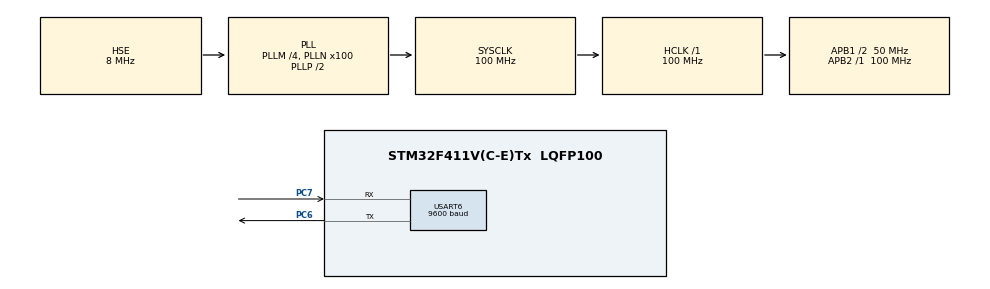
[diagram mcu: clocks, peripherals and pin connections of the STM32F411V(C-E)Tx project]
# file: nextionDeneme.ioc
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Mcu.Family=STM32F4
Mcu.Name=STM32F411V(C-E)Tx
Mcu.Package=LQFP100
NVIC.PriorityGroup=NVIC_PRIORITYGROUP_0
PC6.Mode=Asynchronous
PC6.Signal=USART6_TX
PC7.Mode=Asynchronous
PC7.Signal=USART6_RX
PH0\ -\ OSC_IN.Mode=HSE-External-Oscillator
PH0\ -\ OSC_IN.Signal=RCC_OSC_IN
PH1\ -\ OSC_OUT.Mode=HSE-External-Oscillator
PH1\ -\ OSC_OUT.Signal=RCC_OSC_OUT
ProjectManager.HeapSize=0x200
ProjectManager.StackSize=0x400
ProjectManager.TargetToolchain=STM32CubeIDE
RCC.48MHZClocksFreq_Value=25000000
RCC.AHBFreq_Value=100000000
RCC.APB1CLKDivider=RCC_HCLK_DIV2
RCC.APB1Freq_Value=50000000
RCC.APB1TimFreq_Value=100000000
RCC.APB2Freq_Value=100000000
RCC.APB2TimFreq_Value=100000000
RCC.CortexFreq_Value=100000000
RCC.HCLKFreq_Value=100000000
RCC.HSE_VALUE=8000000
RCC.HSI_VALUE=16000000
RCC.LSE_VALUE=32768
RCC.PLLI2SM=5
RCC.PLLI2SN=200
RCC.PLLM=4
RCC.PLLN=100
RCC.PLLQ=8
RCC.PLLSourceVirtual=RCC_PLLSOURCE_HSE
RCC.SYSCLKFreq_VALUE=100000000
RCC.SYSCLKSource=RCC_SYSCLKSOURCE_PLLCLK
RCC.VCOOutputFreq_Value=200000000
USART6.BaudRate=9600
USART6.VirtualMode=VM_ASYNC
board=STM32F411E-DISCO

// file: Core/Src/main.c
/* USER CODE BEGIN Header */
/**
  ******************************************************************************
  * @file           : main.c
  * @brief          : Main program body
  ******************************************************************************
  * @attention
  *
  * Copyright (c) 2023 STMicroelectronics.
  * All rights reserved.
  *
  * This software is licensed under terms that can be found in the LICENSE file
  * in the root directory of this software component.
  * If no LICENSE file comes with this software, it is provided AS-IS.
  *
  ******************************************************************************
  */
/* USER CODE END Header */
#include "main.h"

/* USER CODE BEGIN Includes */
#include "stdio.h"
#include "nextion.h"
/* USER CODE END Includes */

 UART_HandleTypeDef huart6;

void SystemClock_Config(void);
static void MX_GPIO_Init(void);
static void MX_USART6_UART_Init(void);

/* USER CODE BEGIN 0 */

uint16_t speedvalue=0;
uint16_t fuelvalue=0;
uint16_t totalvoltvalue=0;
uint16_t totalcurrentvalue=0;
uint16_t maxtempvalue=0;
uint16_t mintempvalue=0;
uint16_t maxvoltvalue=0;
uint16_t minvoltvalue=0;
uint16_t phase1value=0;
uint16_t phase2value=0;
uint16_t phase3value=0;
uint16_t cell1num1value=0;
uint16_t cell1num2value=0;
uint16_t cell1num3value=0;
uint16_t cell1num4value=0;
uint16_t cell1num5value=0;
uint16_t cell1num6value=0;
uint16_t cell1num7value=0;
uint16_t cell1num8value=0;
uint16_t cell1num9value=0;
uint16_t cell1num10value=0;
uint16_t cell2num1value=0;
uint16_t cell2num2value=0;
uint16_t cell2num3value=0;
uint16_t cell2num4value=0;
uint16_t cell2num5value=0;
uint16_t cell2num6value=0;
uint16_t cell2num7value=0;
uint16_t cell2num8value=0;
uint16_t cell2num9value=0;
uint16_t cell2num10value=0;

float speedFloat;

/* USER CODE END 0 */

int main(void)
{

  /* MCU Configuration--------------------------------------------------------*/

  /* Reset of all peripherals, Initializes the Flash interface and the Systick. */
  HAL_Init();

  /* Configure the system clock */
  SystemClock_Config();

  /* Initialize all configured peripherals */
  MX_GPIO_Init();
  MX_USART6_UART_Init();

  /* Infinite loop */
  while (1)
  {

    /* USER CODE BEGIN 3 */
	  if(speedvalue < 288)
	  {
		  SpeedGauge("z0.val", speedvalue);

		  speedFloat = ((float)speedvalue/288.0)*100;
		  SpeedNum("n1.val", speedFloat);

		  speedvalue++;

		  HAL_Delay (10);
	  }

	  if(fuelvalue < 180)
	  {
		  FuelGauge("z1.val", fuelvalue);
		  FuelNum("n0.val", fuelvalue);
		  fuelvalue++;
		  HAL_Delay(10);
	  }

	  if(totalvoltvalue<50)
	  {
		  TotalVoltNum("n2.val", totalvoltvalue);
		  totalvoltvalue++;
		  HAL_Delay(10);
	  }

	  if(maxtempvalue<500)
	  {
		  TotalVoltNum("n0s.val", maxtempvalue);
		  maxtempvalue++;
		  HAL_Delay(10);
	  }

	  if(cell1num1value<100)
	  {
		  Cell1Num1Num("n0t.val", cell1num1value);
		  cell1num1value++;
		  HAL_Delay(10);
	  }
  }
  /* USER CODE END 3 */
}

void SystemClock_Config(void)
{
  RCC_OscInitTypeDef RCC_OscInitStruct = {0};
  RCC_ClkInitTypeDef RCC_ClkInitStruct = {0};

  /** Configure the main internal regulator output voltage
  */
  __HAL_RCC_PWR_CLK_ENABLE();
  __HAL_PWR_VOLTAGESCALING_CONFIG(PWR_REGULATOR_VOLTAGE_SCALE1);

  /** Initializes the RCC Oscillators according to the specified parameters
  * in the RCC_OscInitTypeDef structure.
  */
  RCC_OscInitStruct.OscillatorType = RCC_OSCILLATORTYPE_HSE;
  RCC_OscInitStruct.HSEState = RCC_HSE_ON;
  RCC_OscInitStruct.PLL.PLLState = RCC_PLL_ON;
  RCC_OscInitStruct.PLL.PLLSource = RCC_PLLSOURCE_HSE;
  RCC_OscInitStruct.PLL.PLLM = 4;
  RCC_OscInitStruct.PLL.PLLN = 100;
  RCC_OscInitStruct.PLL.PLLP = RCC_PLLP_DIV2;
  RCC_OscInitStruct.PLL.PLLQ = 8;
  if (HAL_RCC_OscConfig(&RCC_OscInitStruct) != HAL_OK)
  {
    Error_Handler();
  }

  /** Initializes the CPU, AHB and APB buses clocks
  */
  RCC_ClkInitStruct.ClockType = RCC_CLOCKTYPE_HCLK|RCC_CLOCKTYPE_SYSCLK
                              |RCC_CLOCKTYPE_PCLK1|RCC_CLOCKTYPE_PCLK2;
  RCC_ClkInitStruct.SYSCLKSource = RCC_SYSCLKSOURCE_PLLCLK;
  RCC_ClkInitStruct.AHBCLKDivider = RCC_SYSCLK_DIV1;
  RCC_ClkInitStruct.APB1CLKDivider = RCC_HCLK_DIV2;
  RCC_ClkInitStruct.APB2CLKDivider = RCC_HCLK_DIV1;

  if (HAL_RCC_ClockConfig(&RCC_ClkInitStruct, FLASH_LATENCY_3) != HAL_OK)
  {
    Error_Handler();
  }
}

static void MX_USART6_UART_Init(void)
{

  huart6.Instance = USART6;
  huart6.Init.BaudRate = 9600;
  huart6.Init.WordLength = UART_WORDLENGTH_8B;
  huart6.Init.StopBits = UART_STOPBITS_1;
  huart6.Init.Parity = UART_PARITY_NONE;
  huart6.Init.Mode = UART_MODE_TX_RX;
  huart6.Init.HwFlowCtl = UART_HWCONTROL_NONE;
  huart6.Init.OverSampling = UART_OVERSAMPLING_16;
  if (HAL_UART_Init(&huart6) != HAL_OK)
  {
    Error_Handler();
  }

}

static void MX_GPIO_Init(void)
{

  /* GPIO Ports Clock Enable */
  __HAL_RCC_GPIOH_CLK_ENABLE();
  __HAL_RCC_GPIOC_CLK_ENABLE();

}

void Error_Handler(void)
{
  __disable_irq();
  while (1)
  {
  }
}
